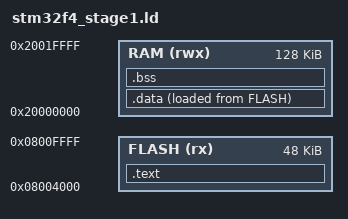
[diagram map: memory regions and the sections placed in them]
/**
 * STM32F407 Linker Script for E-Boot Stage-1
 *
 * Stage-1 starts at 0x08004000, 48K of flash.
 * RAM: 128K SRAM (0x20000000 - 0x2001FFFF)
 */

MEMORY
{
    FLASH (rx)  : ORIGIN = 0x08004000, LENGTH = 48K
    RAM   (rwx) : ORIGIN = 0x20000000, LENGTH = 128K
}

_estack = ORIGIN(RAM) + LENGTH(RAM);

SECTIONS
{
    .text :
    {
        . = ALIGN(4);
        *(.text)
        *(.text*)
        *(.rodata)
        *(.rodata*)
        . = ALIGN(4);
        _etext = .;
    } > FLASH

    _sidata = LOADADDR(.data);

    .data :
    {
        . = ALIGN(4);
        _sdata = .;
        *(.data)
        *(.data*)
        . = ALIGN(4);
        _edata = .;
    } > RAM AT> FLASH

    .bss :
    {
        . = ALIGN(4);
        _sbss = .;
        *(.bss)
        *(.bss*)
        *(COMMON)
        . = ALIGN(4);
        _ebss = .;
    } > RAM
}
